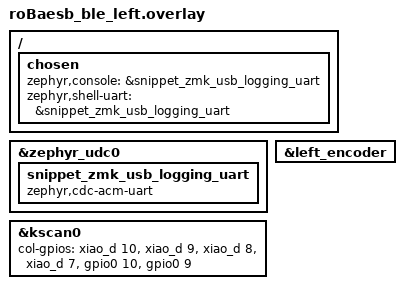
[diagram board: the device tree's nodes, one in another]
#include "../roBa/roBa.dtsi"
#include "roBaesb_ble_addr.dtsi"

/ {
    chosen {
        zephyr,console = &snippet_zmk_usb_logging_uart;
        zephyr,shell-uart = &snippet_zmk_usb_logging_uart;
    };
};

&zephyr_udc0 {
    snippet_zmk_usb_logging_uart: snippet_zmk_usb_logging_uart {
        compatible = "zephyr,cdc-acm-uart";
    };
};

&kscan0 {
    col-gpios
        = <&xiao_d 10 GPIO_ACTIVE_HIGH>
        , <&xiao_d 9 GPIO_ACTIVE_HIGH>
        , <&xiao_d 8 GPIO_ACTIVE_HIGH>
        , <&xiao_d 7 GPIO_ACTIVE_HIGH>
        , <&gpio0 10 GPIO_ACTIVE_HIGH>
        , <&gpio0 9 GPIO_ACTIVE_HIGH>
        ;
};

&left_encoder {
    status = "okay";
};
